# CY8C4246AZI_L445 register map
File version: 0.1
Registers are 32-bit, read-write, no defined reset value unless marked. A register's access mark holds for its fields unless they carry their own. Offsets are from the block's base; [hi:lo] are bit positions; {n}, {i} and the like mark numbered series; 'fields as' and 'values as' point back to an identical list.

## USBFS
Base 0x00000000
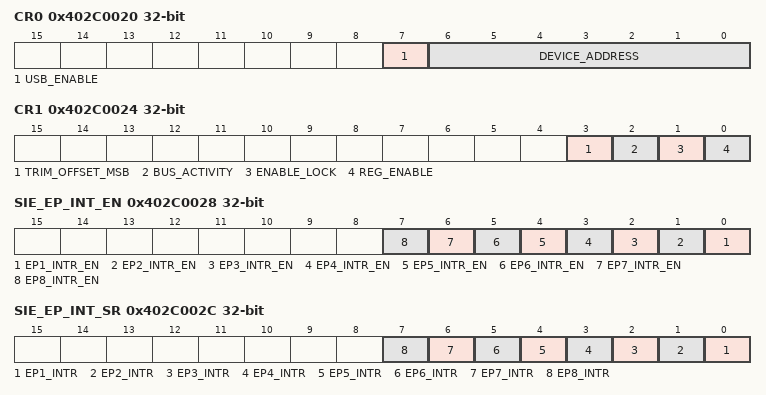
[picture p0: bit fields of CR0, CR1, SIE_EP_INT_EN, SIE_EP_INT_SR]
0x402C0020 CR0 — USB Control 0 Register
  [7] USB_ENABLE — This bit enables the device to respond to USB traffic.
    0=Disabled (Block responds to USB traffic.); 1=Enabled (Block does not respond to USB traffic.)
  [6:0] DEVICE_ADDRESS ro — These bits specify the USB device address to which the SIE will respond. This address must be set by firmware and is specified by the USB Host with a SET ADDRESS command during USB enumeration. This value must be programmed by firmware when assigned during enumeration. It is not set automatically by the hardware.
0x402C0024 CR1 — USB Control 1 Register
  [3] TRIM_OFFSET_MSB — This bit enables trim bit[7].
  [2] BUS_ACTIVITY — The Bus Activity bit is a stickybit that detects any non-idle USB event that has occurred on the USB bus. Once set to High by the SIE to indicate the bus activity this bit retains its logical High value until firmware clears it.
  [1] ENABLE_LOCK — This bit is set to turn on the automatic frequency locking of the internal oscillator to USB traffic. Unless an external clock is being provided this bit should remain set for proper USB operation.
  [0] REG_ENABLE ro — This bit controls the operation of the internal USB regulator. For applications with supply voltages in the 5V range this bit is set high to enable the internal regulator. For device supply voltage in the 3.3V range this bit is cleared to connect the transceiver directly to the supply.
    0=Disabled (Regulator for 5V is disabled.); 1=Enabled (Regulator for 5V is enabled.)
0x402C0028 SIE_EP_INT_EN — USB SIE Data Endpoints Interrupt Enable Register
  [n-1] EP{n}_INTR_EN (n=1..8) — Enables interrupt for EP{n}.
0x402C002C SIE_EP_INT_SR — SIE Data Endpoint Interrupt Status Register
  [n-1] EP{n}_INTR (n=1..8) — Interrupt status for EP{n}.
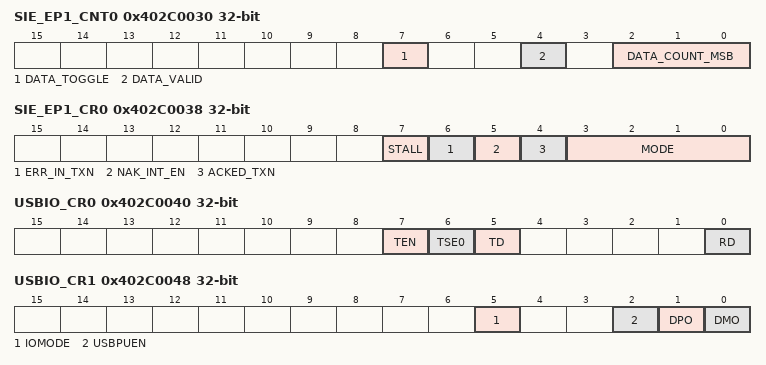
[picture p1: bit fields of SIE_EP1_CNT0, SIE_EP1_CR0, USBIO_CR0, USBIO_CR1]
0x402C0030 SIE_EP1_CNT0 — SIE Endpoint 1 Count0 Register
  [7] DATA_TOGGLE — This bit selects the DATA packet's toggle state. For IN transactions firmware must set this bit to the expected state. For OUT transactions the hardware sets this bit to the state of the received Data Toggle bit.
  [4] DATA_VALID — DATA_ERROR - 0, DATA_VALID - 1.
  [2:0] DATA_COUNT_MSB — These bits are the 3 MSb bits of an 11-bit counter. The LSb are the Data Count[7:0] bits of the CNT1 register. Refer to the CNT1 register for more information.
0x402C0034 SIE_EP1_CNT1 — SIE Endpoint 1 Count1 Register
  [7:0] DATA_COUNT — These bits are the 8 LSb of a 11-bit counter. The 3 MSb bits are in the CNT0 register. The 11-bit count indicates the number of data bytes in a transaction.
0x402C0038 SIE_EP1_CR0 — SIE Endpoint 1 Control Register
  [7] STALL — When this bit is set the SIE stalls an OUT packet if the Mode bits are set to ACK-OUT. The SIE stalls an IN packet if the mode bits are set to ACK-IN. This bit must be clear for all other modes.
  [6] ERR_IN_TXN — The Error in transaction bit is set whenever an error is detected.
  [5] NAK_INT_EN — When set this bit causes an endpoint interrupt to be generated even when a transfer completes with a NAK.
  [4] ACKED_TXN — ACKED_NO - 0, ACKED_YES - 1.
  [3:0] MODE — The mode controls how the USB SIE responds to traffic and how the USB SIE changes the mode of that endpoint as a result of host packets to the endpoint.
    0=DISABLE (Ignore all USB traffic to this endpoint.); 1=NAK_INOUT (SETUP: Accept, IN: NAK, OUT: NAK.); 2=STATUS_OUT_ONLY (SETUP: Accept, IN: STALL, OUT: ACK 0B tokens, NAK others.); 3=STALL_INOUT (SETUP: Accept, IN: STALL, OUT: STALL.); 5=ISO_OUT (SETUP: Ignore, IN: Ignore, OUT: Accept Isochronous OUT token.); 6=STATUS_IN_ONLY (SETUP: Accept, IN: Respond with 0B data, OUT: Stall.); 7=ISO_IN (SETUP: Ignore, IN: Accept Isochronous IN token, OUT: Ignore.); 8=NAK_OUT (SETUP: Ignore, IN: Ignore, OUT: NAK.); 9=ACK_OUT (SETUP: Ignore, IN: Ignore, OUT: Accept data and ACK if STALL = 0, STALL otherwise. Change to MODE=8 after one succesfull OUT token.); 11=ACK_OUT_STATUS_IN (SETUP: Accept, IN: Respond with 0B data, OUT: Accept data.); 12=NAK_IN (SETUP: Ignore, IN: NAK, OUT: Ignore.); 13=ACK_IN (SETUP: Ignore, IN: Respond to IN with data if STALL=0, STALL otherwise, OUT: Ignore); 15=ACK_IN_STATUS_OUT (SETUP: Accept, IN: Respond to IN with data, OUT: ACK 0B tokens, NAK others.)
0x402C0040 USBIO_CR0 — USBIO Control 0 Register
  [7] TEN — USB Transmit Enable. This is used to manually transmit on the D+ and D- pins. Normally this bit should be cleared to allow the internal SIE to drive the pins. The most common reason for manually transmitting is to force a resume state on the bus.
  [6] TSE0 — Transmit Single-Ended Zero. SE0: both D+ and D- low. No effect if TEN=0.
  [5] TD — Transmit Data. Transmit a USB J or K state on the USB bus. No effect if TEN=0 or TSE0=1.
    0=DIFF_K (Force USB K state (D+ is low D- is high).); 1=DIFF_J (Force USB J state (D+ is high D- is low).)
  [0] RD ro — Received Data. This read only bit gives the state of the USB differential receiver.
    0=DIFF_LOW (D+ less than D- (K state), or D+=D-=0 (SE0).); 1=DIFF_HIGH (D+ greater than D- (J state).)
0x402C0048 USBIO_CR1 — USBIO Control 1 Register
  [5] IOMODE — This bit allows the D+ and D- pins to be configured for either USB mode or bit-banged modes. If this bit is set the DMI and DPI bits are used to drive the D- and D+ pins.
    0=Bit-banged mode for Dm and Dp; 1=USB (USB block controls Dm and Dp.)
  [2] USBPUEN — This bit enables the connection of the internal 1.5 k pull up resistor on the D+ pin.
  [1] DPO ro — This read only bit gives the state of the D+ pin.
  [0] DMO ro — This read only bit gives the state of the D- pin.
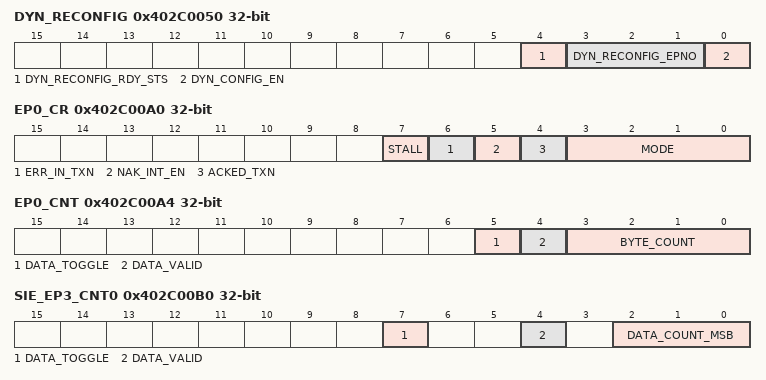
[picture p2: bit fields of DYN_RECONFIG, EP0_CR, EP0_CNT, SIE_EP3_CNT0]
0x402C0050 DYN_RECONFIG — USB Dynamic reconfiguration Register
  [4] DYN_RECONFIG_RDY_STS ro — This bit indicates the ready status for the dynamic reconfiguration, when set to 1, indicates the block is ready for reconfiguration.
  [3:1] DYN_RECONFIG_EPNO — These bits indicates the EP number for which reconfiguration is required when dyn_config_en bit is set to 1.
  [0] DYN_CONFIG_EN — This bit is used to enable the dynamic re-configuration for the selected EP. If set to 1, indicates the reconfiguration required for selected EP. Use 0 for EP1, 1 for EP2, etc.
0x402C00A0 EP0_CR — Endpoint0 control Register
  fields as SIE_EP1_CR0
0x402C00A4 EP0_CNT — Endpoint0 control Register
  [5] DATA_TOGGLE — This bit selects the DATA packet's toggle state. For IN transactions firmware must set this bit to the expected state. For OUT transactions the hardware sets this bit to the state of the received Data Toggle bit.
  [4] DATA_VALID — This bit is used for OUT/SETUP transactions only and is read only. It is cleared to '0' if CRC bit stuffing errors or PID errors occur. This bit does not update for some endpoint mode settings.
    0=DATA_ERROR (No ACK'd transactions since bit was last cleared.); 1=DATA_VALID (Indicates a transaction ended with an ACK.)
  [3:0] BYTE_COUNT — These bits indicate the number of data bytes in a transaction. For IN transactions firmware loads the count with the number of bytes to be transmitted to the host from the endpoint FIFO. Valid values are 0 to 8. For OUT or SETUP transactions the count is updated by hardware to the number of data bytes received plus two for the CRC bytes. Valid values are 2 to 10.
0x402C00B0 SIE_EP3_CNT0 — SIE Endpoint 1 Count0 Register
  fields as SIE_EP1_CNT0
0x402C00B4 SIE_EP3_CNT1 — SIE Endpoint 1 Count1 Register
  fields as SIE_EP1_CNT1
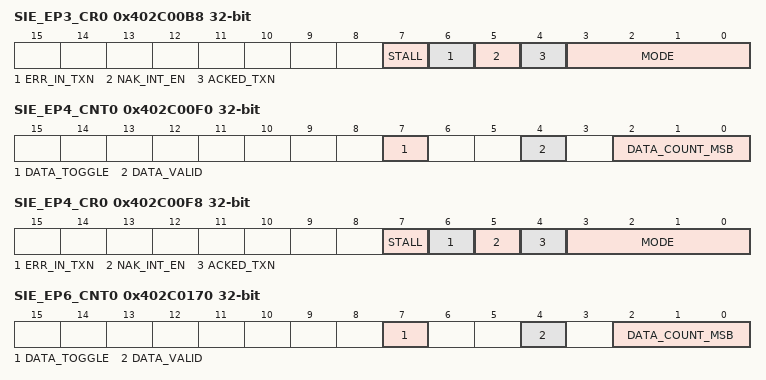
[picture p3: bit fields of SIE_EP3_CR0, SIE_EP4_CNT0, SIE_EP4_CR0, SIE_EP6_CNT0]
0x402C00B8 SIE_EP3_CR0 — SIE Endpoint 1 Control Register
  fields as SIE_EP1_CR0
0x402C00F0 SIE_EP4_CNT0 — SIE Endpoint 1 Count0 Register
  fields as SIE_EP1_CNT0
0x402C00F4 SIE_EP4_CNT1 — SIE Endpoint 1 Count1 Register
  fields as SIE_EP1_CNT1
0x402C00F8 SIE_EP4_CR0 — SIE Endpoint 1 Control Register
  fields as SIE_EP1_CR0
0x402C0170 SIE_EP6_CNT0 — SIE Endpoint 1 Count0 Register
  fields as SIE_EP1_CNT0
0x402C0174 SIE_EP6_CNT1 — SIE Endpoint 1 Count1 Register
  fields as SIE_EP1_CNT1
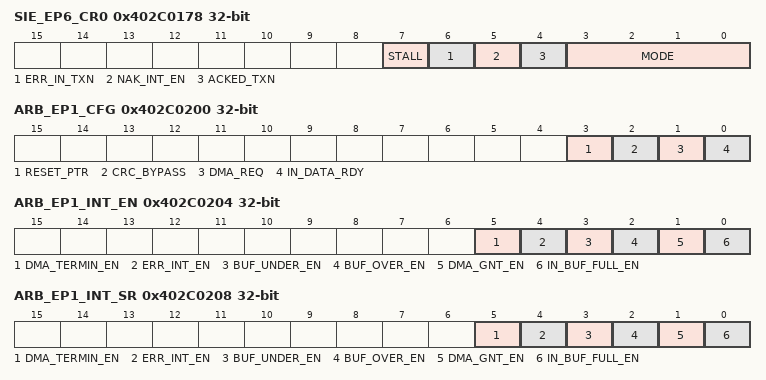
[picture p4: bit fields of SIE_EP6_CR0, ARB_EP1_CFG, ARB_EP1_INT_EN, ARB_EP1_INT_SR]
0x402C0178 SIE_EP6_CR0 — SIE Endpoint 1 Control Register
  fields as SIE_EP1_CR0
0x402C0200 ARB_EP1_CFG — Arbiter Endpoint 1 Configuration Register
  [3] RESET_PTR — RESET_KRYPTON - 0, RESET_NORMAL - 1
  [2] CRC_BYPASS — CRC_NORMAL - 0, CRC_BYPASS - 1
  [1] DMA_REQ — Manual DMA Request for a particular (1 to 8) endpoint; changing this field from 0 to 1 causes a DMA request to be generated.
  [0] IN_DATA_RDY — Indication that Endpoint Packet Data is Ready in Main memory
0x402C0204 ARB_EP1_INT_EN — Arbiter Endpoint 1 Interrupt Enable Register
  [5] DMA_TERMIN_EN — Endpoint DMA Terminated Enable
  [4] ERR_INT_EN — Endpoint Error in Transaction Interrupt
  [3] BUF_UNDER_EN — Endpoint Buffer Underflow
  [2] BUF_OVER_EN — Endpoint Buffer Overflow
  [1] DMA_GNT_EN — Endpoint DMA Grant
  [0] IN_BUF_FULL_EN — IN Endpoint Local Buffer Full
0x402C0208 ARB_EP1_INT_SR — Arbiter Endpoint 1 Interrupt Status Register
  fields as ARB_EP1_INT_EN
0x402C0210 ARB_RW1_WA — Arbiter Endpoint 1 Write Address LSB Register
  [7:0] WA8 — Write Address for EP.
0x402C0214 ARB_RW1_WA_MSB — Arbiter Endpoint 1 Write Address MSB Register
  [0] WA9 — Write Address for EP MSB.
0x402C0218 ARB_RW1_RA — Arbiter Endpoint 1 Read Address LSB Register
  [7:0] RA8 — Read Address for EP MSB.
0x402C021C ARB_RW1_RA_MSB — Arbiter Endpoint 1 Read Address MSB Register
  [0] RA9 — Read Address for EP MSB.
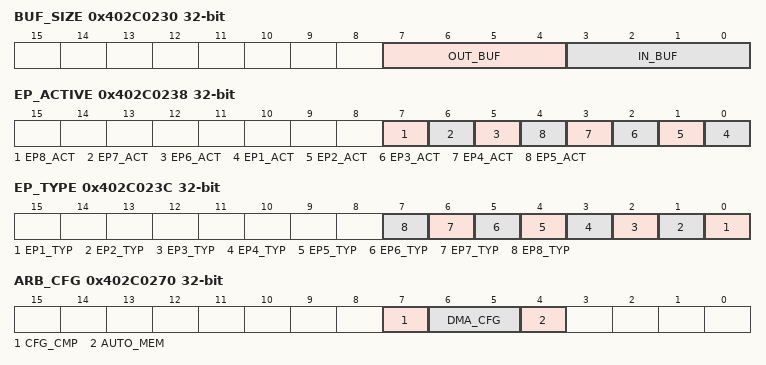
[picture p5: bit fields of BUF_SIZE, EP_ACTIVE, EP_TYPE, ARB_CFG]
0x402C0230 BUF_SIZE — Dedicated Endpoint Buffer Size Register
  [7:4] OUT_BUF — Buffer size for OUT Endpoints: 1 - 2 bytes, 2 - 4 bytes; 9 - 512 bytes.
  [3:0] IN_BUF — Buffer size for IN Endpoints: 1 - 2 bytes, 2 - 4 bytes; 9 - 512 bytes.
0x402C0238 EP_ACTIVE — Endpoint Active Indication Register
  [7] EP8_ACT ro — Indicates that EP8 is currently active
  [6] EP7_ACT ro — Indicates that EP7 is currently active
  [5] EP6_ACT ro — Indicates that EP6 is currently active6
  [n-1] EP{n}_ACT ro (n=1..5) — Indicates that EP{n} is currently active
0x402C023C EP_TYPE — Endpoint Type (IN/OUT) Indication
  [all] fields
    0=EP_IN (IN outpoint.); 1=EP_OUT (OUT outpoint.)
  [n-1] EP{n}_TYP (n=1..8) — Endpoint Type Indication.
0x402C0270 ARB_CFG — Arbiter configuration register
  [7] CFG_CMP — Register Configuration Complete Indication. Posedge is detected on this bit. Hence a 0 to 1 transition is required.
  [6:5] DMA_CFG — DMA Access Configuration.
    0=DMA_NONE (No DMA.); 1=DMA_MANUAL (Manual DMA.); 2=DMA_AUTO (Auto DMA.)
  [4] AUTO_MEM — Enables Auto Memory Configuration. Manual memory configuration by default.
0x402C0274 USB_CLK_EN — USB Control 0 Register
  [7] CSR_CLK_EN — Clock Enable for Core Logic clocked by AHB bus clock.
    0=Disabled (Disables clock to UBS block.); 1=Enabled (Enables clock to UBS block.)
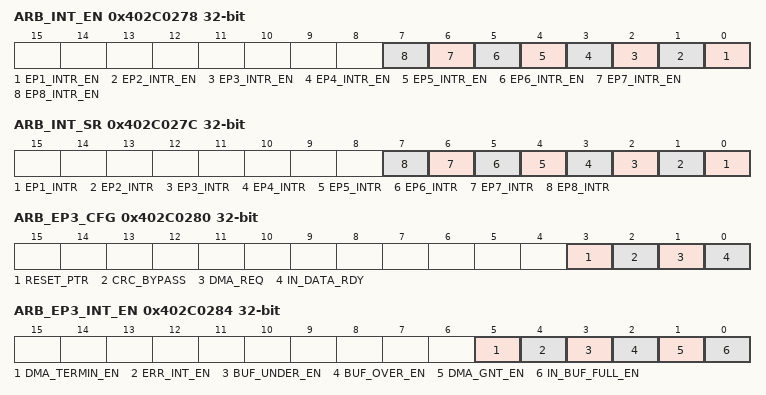
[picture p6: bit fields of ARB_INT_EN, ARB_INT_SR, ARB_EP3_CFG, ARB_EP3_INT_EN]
0x402C0278 ARB_INT_EN — Arbiter Interrupt Enable Register
  [n-1] EP{n}_INTR_EN (n=1..8) — Enables interrupt for EP{n}.
0x402C027C ARB_INT_SR — Arbiter Interrupt Status
  [n-1] EP{n}_INTR ro (n=1..8) — Interrupt status for EP{n}.
0x402C0280 ARB_EP3_CFG — Arbiter Endpoint 1 Configuration Register
  fields as ARB_EP1_CFG
0x402C0284 ARB_EP3_INT_EN — Arbiter Endpoint 1 Interrupt Enable Register
  fields as ARB_EP1_INT_EN
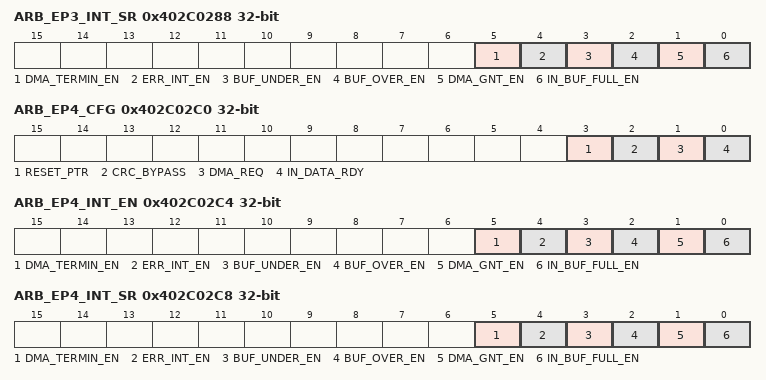
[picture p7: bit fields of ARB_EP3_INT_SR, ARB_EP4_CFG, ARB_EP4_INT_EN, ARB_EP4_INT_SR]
0x402C0288 ARB_EP3_INT_SR — Arbiter Endpoint 1 Interrupt Status Register
  fields as ARB_EP1_INT_EN
0x402C0290 ARB_RW3_WA — Arbiter Endpoint 1 Write Address LSB Register
  [7:0] WA8 — Write Address for EP.
0x402C0294 ARB_RW3_WA_MSB — Arbiter Endpoint 1 Write Address MSB Register
  [0] WA9 — Write Address for EP MSB.
0x402C0298 ARB_RW3_RA — Arbiter Endpoint 1 Read Address LSB Register
  [7:0] RA8 — Read Address for EP MSB.
0x402C029C ARB_RW3_RA_MSB — Arbiter Endpoint 1 Read Address MSB Register
  [0] RA9 — Read Address for EP MSB.
0x402C02B0 CWA — Common Area Write Address LSB Register
  [7:0] WA8 — Write Address for Common Area.
0x402C02B4 CWA_MSB — Common Area Write Address LSB Register
  [0] WA9 — Write Address for Common Area MSB.
0x402C02C0 ARB_EP4_CFG — Arbiter Endpoint 1 Configuration Register
  fields as ARB_EP1_CFG
0x402C02C4 ARB_EP4_INT_EN — Arbiter Endpoint 1 Interrupt Enable Register
  fields as ARB_EP1_INT_EN
0x402C02C8 ARB_EP4_INT_SR — Arbiter Endpoint 1 Interrupt Status Register
  fields as ARB_EP1_INT_EN
0x402C02D0 ARB_RW4_WA — Arbiter Endpoint 1 Write Address LSB Register
  [7:0] WA8 — Write Address for EP.
0x402C02D4 ARB_RW4_WA_MSB — Arbiter Endpoint 1 Write Address MSB Register
  [0] WA9 — Write Address for EP MSB.
0x402C02D8 ARB_RW4_RA — Arbiter Endpoint 1 Read Address LSB Register
  [7:0] RA8 — Read Address for EP MSB.
0x402C02DC ARB_RW4_RA_MSB — Arbiter Endpoint 1 Read Address MSB Register
  [0] RA9 — Read Address for EP MSB.
0x402C02F0 DMA_THRES — DMA Burst / Threshold Configuration LSB Register
  [7:0] WA8 — DMA Threshold count.
0x402C02F4 DMA_THRES_MSB — DMA Burst / Threshold Configuration LSB Register
  [0] WA9 — DMA Threshold count MSB.
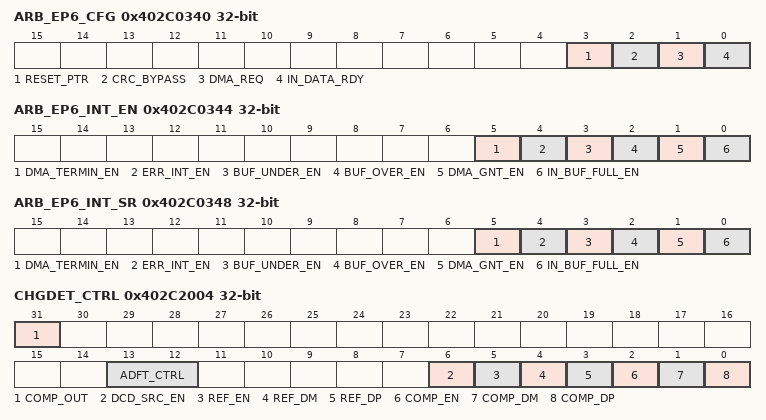
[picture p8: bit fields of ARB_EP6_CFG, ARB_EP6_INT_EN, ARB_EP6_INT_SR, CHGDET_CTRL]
0x402C0340 ARB_EP6_CFG — Arbiter Endpoint 1 Configuration Register
  fields as ARB_EP1_CFG
0x402C0344 ARB_EP6_INT_EN — Arbiter Endpoint 1 Interrupt Enable Register
  fields as ARB_EP1_INT_EN
0x402C0348 ARB_EP6_INT_SR — Arbiter Endpoint 1 Interrupt Status Register
  fields as ARB_EP1_INT_EN
0x402C0350 ARB_RW6_WA — Arbiter Endpoint 1 Write Address LSB Register
  [7:0] WA8 — Write Address for EP.
0x402C0354 ARB_RW6_WA_MSB — Arbiter Endpoint 1 Write Address MSB Register
  [0] WA9 — Write Address for EP MSB.
0x402C0358 ARB_RW6_RA — Arbiter Endpoint 1 Read Address LSB Register
  [7:0] RA8 — Read Address for EP MSB.
0x402C035C ARB_RW6_RA_MSB — Arbiter Endpoint 1 Read Address MSB Register
  [0] RA9 — Read Address for EP MSB.
0x402C2000 POWER_CTRL — Power Control Register
  [31] ENABLE — Mast enable of PHY and Charger Detector. Nothing will work until this bit is set.
  [30] ENABLE_CHGDET — Enables the charger detection circuitry. After USB has connected, this circuitry can be disabled to save power.
  [29] ENABLE_DMO — Enables the signle ended receiver on D-.
  [28] ENABLE_DPO — Enables the single ended receiver on D+.
  [27] ENABLE_RCVR — Enables the differential USB receiver.
  [26] ENABLE_DM_PULLDOWN — Enables the ~15k pull down on the DM, default off. The 15k pull down is needed for Data Contact Detection (DCD).
  [26] ENABLE_VBUS_PULLDOWN — Enables the weak pull down on the VBUS, default on, to prevent floating node crow bar currents.
  [6:5] CHDET_PWR_CTL — Power programmability for bandgap voltage buffer in the charger detect block. See s8bg_vrefbuf public cell for more information. Default '0' is low power mode.
  [4] ISOLATE — Isolates the PHY outputs. Clear this bit at least 2us after vbus is known to be valid (vbus_valid=1). Isolation will be forced when vbus_valid goes low (see VBUS_VALID_OVR).
  [3] SUSPEND_DEL — Delayed version of SUSPEND. Always set SUSPEND and SUSPEND_DEL together in a single register write. When taking PHY out of suspend mode, first clear SUSPEND, then clear SUSPEND_DEL at least 2us later.
  [2] SUSPEND — Put PHY into Suspend mode. If the PHY is enabled, this bit MUST be set before entering a low power mode (DeepSleep/Hibernate).
  [1:0] VBUS_VALID_OVR — Overrides the value received from the GPIO input buffer connected to VBUS
    0=FORCE_VALID_0 (Force vbus_valid = 0.); 1=FORCE_VALID_1 (Force vbus_valid = 1.); 2=GPIO_VALID (Use vbus_valid signal from GPIO input.); 3=PHY_VALID (Use vbus_valid signal from PHY detector.)
0x402C2004 CHGDET_CTRL — Charger Detection Control Register
  [31] COMP_OUT — Output of the primary/secondary detection comparator. This output is not filtered or debounced and must be polled in software.
  [13:12] ADFT_CTRL — ADFT option to bring out buffered version of voltage reference input or adft intput to ADFT output (adft_out).
    0=ADFT_NORMAL (Normal operating mode, reference buffer used to generate internal references. adft_out pulled low.); 1=ADFT_VBG (Use reference buffer to bring out voltage reference input (vbg) onto adft_out.); 2=ADFT_DONTUSE (Illegal - do not use.); 3=ADFT_ADFTIN (Use reference buffer to bring out buffered version of system level adft input (adft_in) onto adft_out.)
  [6] DCD_SRC_EN — Enable the Data Contact Detect current source on D+.
  [5] REF_EN — Enable the primary/secondary reference driver. This bit can be written concurrently with REF_DP/REF_DM.
  [4] REF_DM — Connect the primary/secondary detection reference driver to D-.
  [3] REF_DP — Connect the primary/secondary detection reference driver to D+.
  [2] COMP_EN — Enable the primary/secondary detection comparator and current sink. This bit can be written concurrently with COMP_DP/COMP_DM. Note that REF_EN must also be 1 for the comparator to work (because it receives a reference from it).
  [1] COMP_DM — Connect the primary/secondary detection comparator and current sink to D-.
  [0] COMP_DP — Connect the primary/secondary detection comparator and current sink to D+.
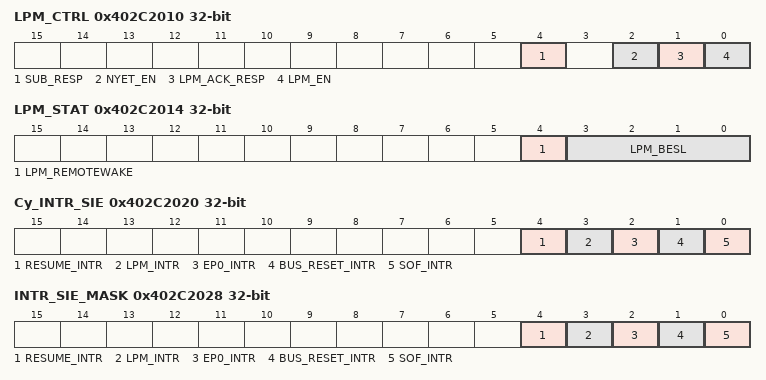
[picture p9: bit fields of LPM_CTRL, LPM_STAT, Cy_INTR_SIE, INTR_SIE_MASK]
0x402C2010 LPM_CTRL — LPM Control Register
  [4] SUB_RESP — Enable a STALL response for all undefined SubPIDs, i.e. other than LPM (0011b). If not enabled then there will be no response (Error) for the undefined SubPIDs.
  [2] NYET_EN — Allow firmware to choose which response to use for an LPM token (LPM_EN=1) when the device is NOT ready to go to the requested low power mode (LPM_ACK_RESP=0).
    0=NYET (A LPM token will get an NAK response (indicating a CRC error), the host is expected to repeat the LPM token.); 1=NACK (A LPM token will get a NYET response.)
  [1] LPM_ACK_RESP — LPM ACK response enable (if LPM_EN=1), to allow firmware to refuse a low power request.
    0=NYET_NACK (A LPM token will get a NYET or NAK (depending on NYET_EN bit below) response and the device will NOT go to a low power mode.); 1=ACK (A LPM token will get an ACK response and the device will go to the requested low power mode.)
  [0] LPM_EN — LPM enable.
    0=Disable (LPM token will not get a response (backward compatibility mode).); 1=Enable (LPM token will get a handshake response (ACK, STALL, NYET or NAK). A STALL will be sent if the bLinkState is not 0001b. A NYET, NAK or ACK response will be sent depending on the NYET_EN and LPM_ACK_RESP bits below.)
0x402C2014 LPM_STAT — LPM Status register
  [4] LPM_REMOTEWAKE — LPM ACK response enable (if LPM_EN=1), to allow firmware to refuse a low power request.
    0=Prohibited (Device is prohibited from initiating a remote wake.); 1=Allowed (Device is allow to wake the host.)
  [3:0] LPM_BESL — Best Effort Service Latency. This value should match either the Baseline (DeepSleep) or Deep (Hibernate) BESL in the BOS descriptor.
0x402C2020 Cy_INTR_SIE — USB SOF, BUS RESET and EP0 Interrupt Status
  [4] RESUME_INTR — Resume Interrupt.
  [3] LPM_INTR — LPM Interrupt.
  [2] EP0_INTR — EP0 Interrupt.
  [1] BUS_RESET_INTR — BUS RESET Interrupt.
  [0] SOF_INTR — USB SOF Interrupt.
0x402C2028 INTR_SIE_MASK — USB SOF, BUS RESET and EP0 Interrupt Mask
  fields as Cy_INTR_SIE
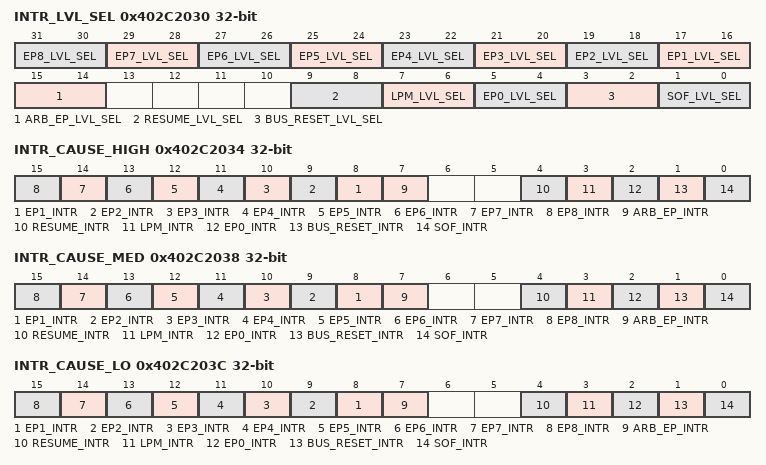
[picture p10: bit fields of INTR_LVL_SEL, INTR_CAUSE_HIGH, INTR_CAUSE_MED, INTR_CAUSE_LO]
0x402C2030 INTR_LVL_SEL — Select interrupt level for each interrupt source
  [2n+15:2n+14] EP{n}_LVL_SEL (n=1..8) — EP{n} Interrupt level select.
  [15:14] ARB_EP_LVL_SEL — Arbiter Endpoint Interrupt level select.
  [9:8] RESUME_LVL_SEL — Resume Interrupt level select.
  [7:6] LPM_LVL_SEL — LPM Interrupt level select.
  [5:4] EP0_LVL_SEL — EP0 Interrupt level select.
  [3:2] BUS_RESET_LVL_SEL — BUS RESET Interrupt level select.
  [1:0] SOF_LVL_SEL — USB SOF Interrupt level select.
0x402C2034 INTR_CAUSE_HIGH — High priority interrupt Cause register
  [n+7] EP{n}_INTR (n=1..8) — EP1 Interrupt.
  [7] ARB_EP_INTR — Arbiter Endpoint Interrupt.
  [4] RESUME_INTR — Resume Interrupt.
  [3] LPM_INTR — LPM Interrupt.
  [2] EP0_INTR — EP0 Interrupt.
  [1] BUS_RESET_INTR — BUS RESET Interrupt.
  [0] SOF_INTR — USB SOF Interrupt.
0x402C2038 INTR_CAUSE_MED — Medium priority interrupt Cause register
  fields as INTR_CAUSE_HIGH
0x402C203C INTR_CAUSE_LO — Low priority interrupt Cause register
  fields as INTR_CAUSE_HIGH
